# PRU_ICSS_0_UART_local register map
Vendor: Texas Instruments
Peripheral module from a debugger description file (folder 66AK2G0x_66AK2G1x).
Registers are 32-bit, access per field, reset values left out (the file's numbers can be read two ways) unless marked. A register's access mark holds for its fields unless they carry their own. Offsets are as the file gives them; lines under a group give offsets from that group; [hi:lo] are bit positions; {n}, {i} and the like mark numbered series; 'fields as' and 'values as' point back to an identical list; <NAME> marks a mode.

## PRU_ICSS_0_UART
0x00 PRUSS_UART_RBR_THR_REGISTERS
  [7:0] DATA rw — Read: Read Receive Buffer RegisterWrite: Write Transmitter Holding Register .
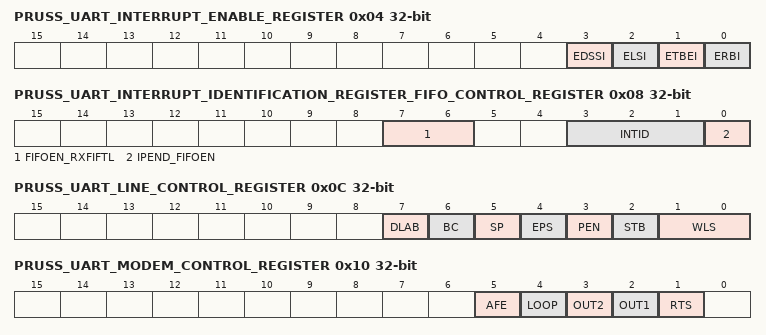
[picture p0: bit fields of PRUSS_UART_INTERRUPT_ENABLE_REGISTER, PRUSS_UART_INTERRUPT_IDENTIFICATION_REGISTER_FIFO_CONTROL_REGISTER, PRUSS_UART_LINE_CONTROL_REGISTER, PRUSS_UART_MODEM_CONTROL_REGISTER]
0x04 PRUSS_UART_INTERRUPT_ENABLE_REGISTER
  [3] EDSSI rw — Enable Modem Status Interrupt
  [2] ELSI rw — Receiver line status interrupt enable.
  [1] ETBEI rw — Transmitter holding register empty interrupt enable.
  [0] ERBI rw — Receiver data available interrupt and character timeout indication interrupt enable.
0x08 PRUSS_UART_INTERRUPT_IDENTIFICATION_REGISTER_FIFO_CONTROL_REGISTER
  [7:6] FIFOEN_RXFIFTL rw — Read: FIFOs enabled. 0h: Non-FIFO modeWrite: Receiver FIFO trigger level. RXFIFTL sets the trigger level for the receiver FIFO. When the trigger level is reached, a receiver data-ready interrupt is generated (if the interrupt request is enabled). Once the FIFO drops below the trigger level, the interrupt is cleared. 0h: 1 byte .
  [3:1] INTID rw — Read: Interrupt type. See . 0h: ReservedWrite: Bit 3: DMAMODE1: DMA MODE1 enable if FIFOs are enabled. Always write 1 to DMAMODE1. After a hardware reset, change DMAMODE1 from 0 to 1. DMAMODE1 = 1 is a requirement for proper communication between the UART and the EDMA controller. 0h: DMA MODE1 is disabled.Bit 2: TXCLR: Transmitter FIFO clear. Write a 1 to TXCLR to clear the bit. 0h: No effect.Bit 1: RXCLR: Receiver FIFO clear. Write a 1 to RXCLR to clear the bit. 0h: No effect. .
  [0] IPEND_FIFOEN rw — Read: Interrupt pending. When any UART interrupt is generated and is enabled in IER, IPEND is forced to 0. IPEND remains 0 until all pending interrupts are cleared or until a hardware reset occurs. If no interrupts are enabled, IPEND is never forced to 0. 0h: Interrupts pending.Write: Transmitter and receiver FIFOs mode enable. FIFOEN must be set before other FCR bits are written to or the FCR bits are not programmed. Clearing this bit clears the FIFO counters. 0h: Non-FIFO mode. The transmitter and receiver FIFOs are disabled, and the FIFO pointers are cleared. .
0x0C PRUSS_UART_LINE_CONTROL_REGISTER
  [7] DLAB rw — Divisor latch access bit. The divisor latch registers (DLL and DLH) can be accessed at dedicated addresses or at addresses shared by RBR, THR, and IER. Using the shared addresses requires toggling DLAB to change which registers are selected. If you use the dedicated addresses, you can keep DLAB = 0.
  [6] BC rw — Break Control.
  [5] SP rw — Stick parity. The SP bit works in conjunction with the EPS and PEN bits. The relationship between the SP, EPS, and PEN bits is summarized in
  [4] EPS rw — Even parity select. Selects the parity when parity is enabled (PEN = 1). The EPS bit works in conjunction with the SP and PEN bits. The relationship between the SP, EPS, and PEN bits is summarized in
  [3] PEN rw — Parity enable. The PEN bit works in conjunction with the SP and EPS bits. The relationship between the SP, EPS, and PEN bits is summarized in
  [2] STB rw — Number of STOP bits generated. STB specifies 1, 1.5, or 2 STOP bits in each transmitted character. When STB = 1, the WLS bit determines the number of STOP bits. The receiver clocks only the first STOP bit, regardless of the number of STOP bits selected. The number of STOP bits generated is summarized in
  [1:0] WLS rw — Word length select. Number of bits in each transmitted or received serial character. When STB = 1, the WLS bit determines the number of STOP bits.
0x10 PRUSS_UART_MODEM_CONTROL_REGISTER
  [5] AFE rw — Autoflow control enable. Autoflow control allows the
  [4] LOOP rw — Loop back mode enable. LOOP is used for the diagnostic testing using the loop back feature.
  [3] OUT2 rw — OUT2 Control Bit
  [2] OUT1 rw — OUT1 Control Bit
  [1] RTS rw — RTS control. When AFE = 1, the RTS bit determines the autoflow control enabled. Note that all UARTs do not support this feature, see your device-specific data manual for supported features. If this feature is not available, this bit is reserved in this device and should be cleared to 0.
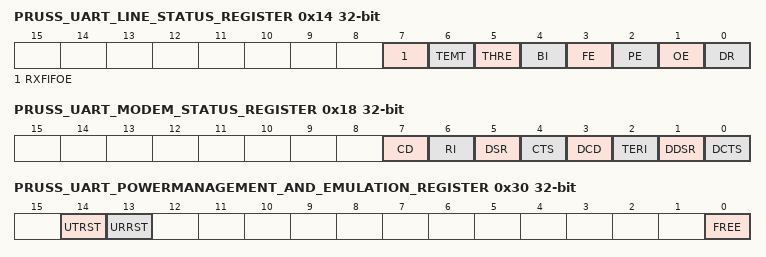
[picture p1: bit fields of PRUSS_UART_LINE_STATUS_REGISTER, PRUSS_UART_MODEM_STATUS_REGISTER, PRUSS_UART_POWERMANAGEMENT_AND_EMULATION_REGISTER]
0x14 PRUSS_UART_LINE_STATUS_REGISTER ro
  [7] RXFIFOE — Receiver FIFO error. .
  [6] TEMT — Transmitter empty (TEMT) indicator. .
  [5] THRE — Transmitter holding register empty (THRE) indicator. If the THRE bit is set and the corresponding interrupt enable bit is set (ETBEI = 1 in IER), an interrupt request is generated. .
  [4] BI — Break indicator. The BI bit is set whenever the receive data input (UARTn_RXD) was held low for longer than a full-word transmission time. A full-word transmission time is defined as the total time to transmit the START, data, PARITY, and STOP bits. If the BI bit is set and the corresponding interrupt enable bit is set (ELSI = 1 in IER), an interrupt request is generated. .
  [3] FE — Framing error (FE) indicator. A framing error occurs when the received character does not have a valid STOP bit. In response to a framing error, the UART sets the FE bit and waits until the signal on the RX pin goes high. Once the RX signal goes high, the receiver is ready to detect a new START bit and receive new data. If the FE bit is set and the corresponding interrupt enable bit is set (ELSI = 1 in IER), an interrupt request is generated. .
  [2] PE — Parity error (PE) indicator. A parity error occurs when the parity of the received character does not match the parity selected with the EPS bit in the line control register (LCR). If the PE bit is set and the corresponding interrupt enable bit is set (ELSI = 1 in IER), an interrupt request is generated. .
  [1] OE — Overrun error (OE) indicator. An overrun error in the non-FIFO mode is different from an overrun error in the FIFO mode. If the OE bit is set and the corresponding interrupt enable bit is set (ELSI = 1 in IER), an interrupt request is generated. .
  [0] DR — Data-ready (DR) indicator for the receiver. If the DR bit is set and the corresponding interrupt enable bit is set (ERBI = 1 in IER), an interrupt request is generated. .
0x18 PRUSS_UART_MODEM_STATUS_REGISTER ro
  [7] CD — Complement of the Carrier Detect input. When the UART is in the diagnostic test mode (loopback mode MCR[4] = 1), this bit is equal to the MCR bit 3 (OUT2)..
  [6] RI — Complement of the Ring Indicator input. When the UART is in the diagnostic test mode (loopback mode MCR[4] = 1), this bit is equal to the MCR bit 2 (OUT1).
  [5] DSR — Complement of the Data Set Ready input. When the UART is in the diagnostic test mode (loopback mode MCR[4] = 1), this bit is equal to the MCR bit 0 (DTR).
  [4] CTS — Complement of the Clear To Send input. When the UART is in the diagnostic test mode (loopback mode MCR[4] = 1), this bit is equal to the MCR bit 1 (RTS).
  [3] DCD — Change in DCD indicator bit. DCD indicates that the DCD input has changed state since the last time it was read by the CPU. When DCD is set and the modem status interrupt is enabled, a modem status interrupt is generated.
  [2] TERI — Trailing edge of RI (TERI) indicator bit. TERI indicates that the RI input has changed from a low to a high. When TERI is set and the modem status interrupt is enabled, a modem status interrupt is generated.
  [1] DDSR — Change in DSR indicator bit. DDSR indicates that the DSR input has changed state since the last time it was read by the CPU. When DDSR is set and the modem status interrupt is enabled, a modem status interrupt is generated.
  [0] DCTS — Change in CTS indicator bit. DCTS indicates that the CTS input has changed state since the last time it was read by the CPU. When DCTS is set (autoflow control is not enabled and the modem status interrupt is enabled), a modem status interrupt is generated. When autoflow control is enabled, no interrupt is generated.
0x1C PRUSS_UART_SCRATCH_REGISTER
  [7:0] DATA rw — These bits are intended for the programmer's use as a scratch pad in the sense that it temporarily holds the programmer's data without affecting any other UART operation.
0x20 PRUSS_UART_DIVISOR_REGISTER_LSB_
  [7:0] DLL rw — The 8 least-significant bits (LSBs) of the 16-bit divisor for generation of the baud clock in the baud rate generator.
0x24 PRUSS_UART_DIVISOR_REGISTER_MSB_
  [7:0] DLH rw — The 8 most-significant bits (MSBs) of the 16-bit divisor for generation of the baud clock in the baud rate generator.
0x28 PRUSS_UART_PERIPHERAL_ID_REGISTER ro
  [31:0] PID
0x30 PRUSS_UART_POWERMANAGEMENT_AND_EMULATION_REGISTER
  [14] UTRST rw — UART transmitter reset. Resets and enables the transmitter.
  [13] URRST rw — UART receiver reset. Resets and enables the receiver.
  [0] FREE rw — Free-running enable mode bit. This bit determines the emulation mode functionality of the UART. When halted, the UART can handle register read/write requests, but does not generate any transmission/reception, interrupts or events.
0x34 PRUSS_UART_MODE_DEFINITION_REGISTER
  [0] OSM_SEL rw — Over-Sampling Mode Select.
